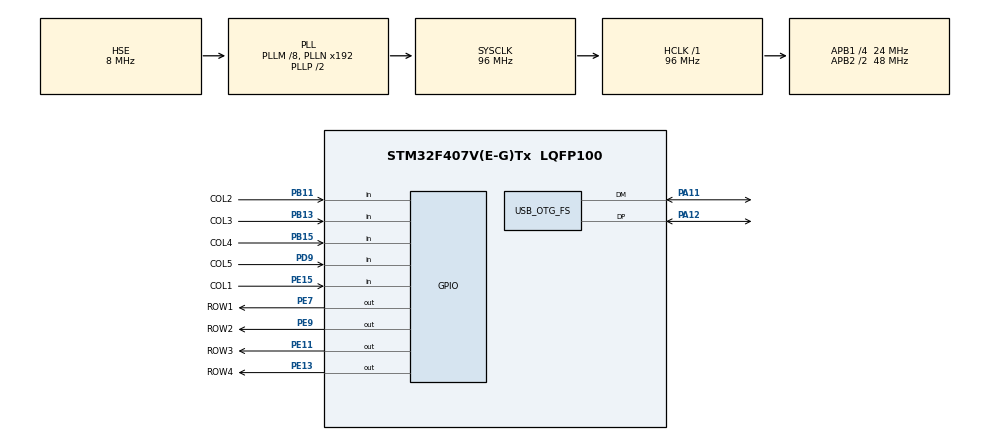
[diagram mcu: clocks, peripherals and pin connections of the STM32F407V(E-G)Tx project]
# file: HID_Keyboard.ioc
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Mcu.Family=STM32F4
Mcu.Name=STM32F407V(E-G)Tx
Mcu.Package=LQFP100
NVIC.OTG_FS_IRQn=true\:0\:0\:false\:false\:true\:false\:true\:true
NVIC.PriorityGroup=NVIC_PRIORITYGROUP_4
PA11.Mode=Device_Only
PA11.Signal=USB_OTG_FS_DM
PA12.Mode=Device_Only
PA12.Signal=USB_OTG_FS_DP
PA13.Mode=Serial_Wire
PA13.Signal=SYS_JTMS-SWDIO
PA14.Mode=Serial_Wire
PA14.Signal=SYS_JTCK-SWCLK
PB11.GPIO_Label=COL2
PB11.GPIO_PuPd=GPIO_PULLUP
PB11.Signal=GPIO_Input
PB13.GPIO_Label=COL3
PB13.GPIO_PuPd=GPIO_PULLUP
PB13.Signal=GPIO_Input
PB15.GPIO_Label=COL4
PB15.GPIO_PuPd=GPIO_PULLUP
PB15.Signal=GPIO_Input
PC14-OSC32_IN.Mode=LSE-External-Oscillator
PC14-OSC32_IN.Signal=RCC_OSC32_IN
PC15-OSC32_OUT.Mode=LSE-External-Oscillator
PC15-OSC32_OUT.Signal=RCC_OSC32_OUT
PD9.GPIO_Label=COL5
PD9.GPIO_PuPd=GPIO_PULLUP
PD9.Signal=GPIO_Input
PE11.GPIO_Label=ROW3
PE11.Signal=GPIO_Output
PE13.GPIO_Label=ROW4
PE13.Signal=GPIO_Output
PE15.GPIO_Label=COL1
PE15.GPIO_PuPd=GPIO_PULLUP
PE15.Signal=GPIO_Input
PE7.GPIO_Label=ROW1
PE7.Signal=GPIO_Output
PE9.GPIO_Label=ROW2
PE9.Signal=GPIO_Output
PH0-OSC_IN.Mode=HSE-External-Oscillator
PH0-OSC_IN.Signal=RCC_OSC_IN
PH1-OSC_OUT.Mode=HSE-External-Oscillator
PH1-OSC_OUT.Signal=RCC_OSC_OUT
ProjectManager.HeapSize=0x200
ProjectManager.StackSize=0x400
ProjectManager.TargetToolchain=STM32CubeIDE
RCC.48MHZClocksFreq_Value=48000000
RCC.AHBFreq_Value=96000000
RCC.APB1CLKDivider=RCC_HCLK_DIV4
RCC.APB1Freq_Value=24000000
RCC.APB1TimFreq_Value=48000000
RCC.APB2CLKDivider=RCC_HCLK_DIV2
RCC.APB2Freq_Value=48000000
RCC.APB2TimFreq_Value=96000000
RCC.CortexFreq_Value=96000000
RCC.HCLKFreq_Value=96000000
RCC.HSE_VALUE=8000000
RCC.HSI_VALUE=16000000
RCC.PLLM=8
RCC.SYSCLKFreq_VALUE=96000000
RCC.SYSCLKSource=RCC_SYSCLKSOURCE_PLLCLK
RCC.VCOOutputFreq_Value=192000000
USB_DEVICE.CLASS_NAME_FS=HID
USB_DEVICE.VirtualMode-HID_FS=Hid
USB_DEVICE.VirtualModeFS=Hid_FS
USB_OTG_FS.VirtualMode=Device_Only
VP_USB_DEVICE_VS_USB_DEVICE_HID_FS.Mode=HID_FS
board=custom

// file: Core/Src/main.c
/* USER CODE BEGIN Header */
/**
  ******************************************************************************
  * @file           : main.c
  * @brief          : Main program body
  ******************************************************************************
  * @attention
  *
  * Copyright (c) 2026 STMicroelectronics.
  * All rights reserved.
  *
  * This software is licensed under terms that can be found in the LICENSE file
  * in the root directory of this software component.
  * If no LICENSE file comes with this software, it is provided AS-IS.
  *
  ******************************************************************************
  */
/* USER CODE END Header */
#include "main.h"
#include "usb_device.h"

/* USER CODE BEGIN Includes */
#include "stm32f4xx_hal.h"
#include "usbd_hid.h"
#include "matrix.h"
/* USER CODE END Includes */

/* USER CODE BEGIN PV */
extern USBD_HandleTypeDef hUsbDeviceFS;
/* USER CODE END PV */

void SystemClock_Config(void);
static void MX_GPIO_Init(void);
/* USER CODE BEGIN PFP */
uint8_t buffer[8];
uint8_t consumerReport[3];
/* USER CODE END PFP */

/* USER CODE BEGIN 0 */
void SendAudioMute(void)
{
    consumerReport[0] = 0x02;   // Consumer Report ID

    consumerReport[1] = 0xE2;   // Audio Mute LSB
    consumerReport[2] = 0x00;   // Audio Mute MSB

    while (((USBD_HID_HandleTypeDef *)hUsbDeviceFS.pClassData)->state == HID_BUSY);

    USBD_HID_SendReport(&hUsbDeviceFS, consumerReport, 3);

    consumerReport[1] = 0x00;
    consumerReport[2] = 0x00;

    while (((USBD_HID_HandleTypeDef *)hUsbDeviceFS.pClassData)->state == HID_BUSY);

    USBD_HID_SendReport(&hUsbDeviceFS, consumerReport, 3);
}

/* USER CODE END 0 */

int main(void)
{

  /* MCU Configuration--------------------------------------------------------*/

  /* Reset of all peripherals, Initializes the Flash interface and the Systick. */
  HAL_Init();

  /* Configure the system clock */
  SystemClock_Config();

  /* Initialize all configured peripherals */
  MX_GPIO_Init();
  MX_USB_DEVICE_Init();
  /* USER CODE BEGIN 2 */
  buffer[0]=1;     //reportID
  buffer[1]=0;     //modifier
  buffer[2]=0;     //OEM
  buffer[3]=0;     //keycode data
  buffer[4]=0;     //keycode data
  buffer[5]=0;     //keycode data
  buffer[6]=0;     //keycode data
  buffer[7]=0;     //keycode data
  /* USER CODE END 2 */

  /* Infinite loop */
  /* USER CODE BEGIN WHILE */
  uint8_t currentKey;
  uint8_t previousKey = 0x00;

  while (1)
  {
	  currentKey = Matrix_Scan();
    /* USER CODE END WHILE */

    /* USER CODE BEGIN 3 */
	  if(currentKey != 0x00 && previousKey == 0x00)
	  {
		  buffer[1] = 0x00;

		  if(currentKey == 0xFD)
		  {
		      SendAudioMute();

		      previousKey = currentKey;
		      continue;
		  }
		  if(currentKey == 0x68)
		  {
		      buffer[3]= currentKey;
		  }
		  if(currentKey == 0xF0)
		  {
		      buffer[1] = 0x02;
		      buffer[3] = 0x20;
		  }
		  else if(currentKey == 0xF1)
		  {
		      buffer[1] = 0x02;
		      buffer[3] = 0x25;
		  }
		  else if(currentKey == 0x1e)
		  {
		      // First press
		      buffer[3] = 0x1e;
		      USBD_HID_SendReport(&hUsbDeviceFS, buffer, 8);

		      HAL_Delay(30);

		      // Release
		      buffer[3] = 0x00;
		      USBD_HID_SendReport(&hUsbDeviceFS, buffer, 8);

		      HAL_Delay(30);

		      // Second press
		      buffer[3] = 0x1e;
		      USBD_HID_SendReport(&hUsbDeviceFS, buffer, 8);

		      HAL_Delay(30);

		      // Final release
		      buffer[3] = 0x00;
		      USBD_HID_SendReport(&hUsbDeviceFS, buffer, 8);

		      previousKey = currentKey;
		      continue;
		  }
		  else
		  {
		      buffer[3] = currentKey;
		  }

		  USBD_HID_SendReport(&hUsbDeviceFS, buffer, 8);

	      previousKey = currentKey;
	  }
	  if(currentKey == 0x00 && previousKey != 0x00)
	  {
		  buffer[1] = 0;
		  buffer[3] = 0x00;

		  while (((USBD_HID_HandleTypeDef *)hUsbDeviceFS.pClassData)->state == HID_BUSY);

		  USBD_HID_SendReport(&hUsbDeviceFS, buffer, 8);

	      previousKey = 0x00;
	  }

  }
  /* USER CODE END 3 */
}

void SystemClock_Config(void)
{
  RCC_OscInitTypeDef RCC_OscInitStruct = {0};
  RCC_ClkInitTypeDef RCC_ClkInitStruct = {0};

  /** Configure the main internal regulator output voltage
  */
  __HAL_RCC_PWR_CLK_ENABLE();
  __HAL_PWR_VOLTAGESCALING_CONFIG(PWR_REGULATOR_VOLTAGE_SCALE1);

  /** Initializes the RCC Oscillators according to the specified parameters
  * in the RCC_OscInitTypeDef structure.
  */
  RCC_OscInitStruct.OscillatorType = RCC_OSCILLATORTYPE_HSE;
  RCC_OscInitStruct.HSEState = RCC_HSE_ON;
  RCC_OscInitStruct.PLL.PLLState = RCC_PLL_ON;
  RCC_OscInitStruct.PLL.PLLSource = RCC_PLLSOURCE_HSE;
  RCC_OscInitStruct.PLL.PLLM = 8;
  RCC_OscInitStruct.PLL.PLLN = 192;
  RCC_OscInitStruct.PLL.PLLP = RCC_PLLP_DIV2;
  RCC_OscInitStruct.PLL.PLLQ = 4;
  if (HAL_RCC_OscConfig(&RCC_OscInitStruct) != HAL_OK)
  {
    Error_Handler();
  }

  /** Initializes the CPU, AHB and APB buses clocks
  */
  RCC_ClkInitStruct.ClockType = RCC_CLOCKTYPE_HCLK|RCC_CLOCKTYPE_SYSCLK
                              |RCC_CLOCKTYPE_PCLK1|RCC_CLOCKTYPE_PCLK2;
  RCC_ClkInitStruct.SYSCLKSource = RCC_SYSCLKSOURCE_PLLCLK;
  RCC_ClkInitStruct.AHBCLKDivider = RCC_SYSCLK_DIV1;
  RCC_ClkInitStruct.APB1CLKDivider = RCC_HCLK_DIV4;
  RCC_ClkInitStruct.APB2CLKDivider = RCC_HCLK_DIV2;

  if (HAL_RCC_ClockConfig(&RCC_ClkInitStruct, FLASH_LATENCY_3) != HAL_OK)
  {
    Error_Handler();
  }
}

static void MX_GPIO_Init(void)
{
  GPIO_InitTypeDef GPIO_InitStruct = {0};

  /* GPIO Ports Clock Enable */
  __HAL_RCC_GPIOC_CLK_ENABLE();
  __HAL_RCC_GPIOH_CLK_ENABLE();
  __HAL_RCC_GPIOE_CLK_ENABLE();
  __HAL_RCC_GPIOB_CLK_ENABLE();
  __HAL_RCC_GPIOD_CLK_ENABLE();
  __HAL_RCC_GPIOA_CLK_ENABLE();

  /*Configure GPIO pin Output Level */
  HAL_GPIO_WritePin(GPIOE, ROW1_Pin|ROW2_Pin|ROW3_Pin|ROW4_Pin, GPIO_PIN_RESET);

  /*Configure GPIO pins : ROW1_Pin ROW2_Pin ROW3_Pin ROW4_Pin */
  GPIO_InitStruct.Pin = ROW1_Pin|ROW2_Pin|ROW3_Pin|ROW4_Pin;
  GPIO_InitStruct.Mode = GPIO_MODE_OUTPUT_PP;
  GPIO_InitStruct.Pull = GPIO_NOPULL;
  GPIO_InitStruct.Speed = GPIO_SPEED_FREQ_LOW;
  HAL_GPIO_Init(GPIOE, &GPIO_InitStruct);

  /*Configure GPIO pin : COL1_Pin */
  GPIO_InitStruct.Pin = COL1_Pin;
  GPIO_InitStruct.Mode = GPIO_MODE_INPUT;
  GPIO_InitStruct.Pull = GPIO_PULLUP;
  HAL_GPIO_Init(COL1_GPIO_Port, &GPIO_InitStruct);

  /*Configure GPIO pins : COL2_Pin COL3_Pin COL4_Pin */
  GPIO_InitStruct.Pin = COL2_Pin|COL3_Pin|COL4_Pin;
  GPIO_InitStruct.Mode = GPIO_MODE_INPUT;
  GPIO_InitStruct.Pull = GPIO_PULLUP;
  HAL_GPIO_Init(GPIOB, &GPIO_InitStruct);

  /*Configure GPIO pin : COL5_Pin */
  GPIO_InitStruct.Pin = COL5_Pin;
  GPIO_InitStruct.Mode = GPIO_MODE_INPUT;
  GPIO_InitStruct.Pull = GPIO_PULLUP;
  HAL_GPIO_Init(COL5_GPIO_Port, &GPIO_InitStruct);

  /*Configure GPIO pin : USER Button */
  GPIO_InitStruct.Pin=GPIO_PIN_0;
  GPIO_InitStruct.Mode=GPIO_MODE_INPUT;
  GPIO_InitStruct.Pull=GPIO_NOPULL;
  HAL_GPIO_Init(GPIOA, &GPIO_InitStruct);

}

void Error_Handler(void)
{
  __disable_irq();
  while (1)
  {
  }
}
